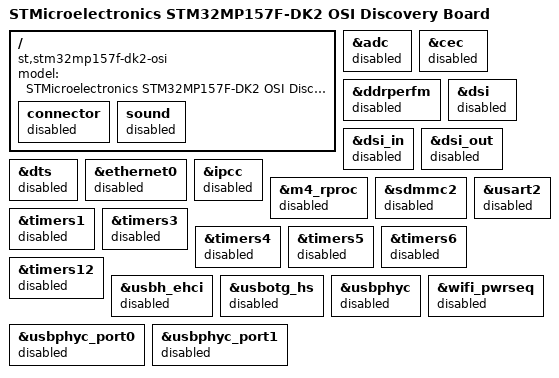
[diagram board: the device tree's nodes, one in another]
// SPDX-License-Identifier: (GPL-2.0-only OR BSD-3-Clause)
/*
 * Copyright (C) STMicroelectronics 2025 - All Rights Reserved
 * Author: Alexandre Torgue <alexandre.torgue@st.com> for STMicroelectronics.
 * Author: Pascal Paillet <p.paillet@st.com> for STMicroelectronics.
 */

/dts-v1/;

#include "stm32mp157f-dk2.dts"

/ {
	model = "STMicroelectronics STM32MP157F-DK2 OSI Discovery Board";
	compatible = "st,stm32mp157f-dk2-osi", "st,stm32mp157f-dk2", "st,stm32mp157";

	connector {
		status = "disabled";
	};

	sound {
		status = "disabled";
	};
};

&adc {
	status = "disabled";
};

&cec {
	status = "disabled";
};

&ddrperfm {
	status = "disabled";
};

&dsi {
	status = "disabled";
};

&dsi_in {
	status = "disabled";
};

&dsi_out {
	status = "disabled";
};

&dts {
	status = "disabled";
};

&ethernet0 {
	status = "disabled";
};

&ipcc {
	status = "disabled";
};

&m4_rproc {
	status = "disabled";
};

&sdmmc2 {
	status = "disabled";
};

&timers1 {
	status = "disabled";
};

&timers3 {
	status = "disabled";
};

&timers4 {
	status = "disabled";
};

&timers5 {
	status = "disabled";
};

&timers6 {
	status = "disabled";
};

&timers12 {
	status = "disabled";
};

&usart2 {
	status = "disabled";
};

&usbh_ehci {
	status = "disabled";
};

&usbotg_hs {
	status = "disabled";
};

&usbphyc {
	status = "disabled";
};

&usbphyc_port0 {
	status = "disabled";
};

&usbphyc_port1 {
	status = "disabled";
};

&wifi_pwrseq {
	status = "disabled";
};
